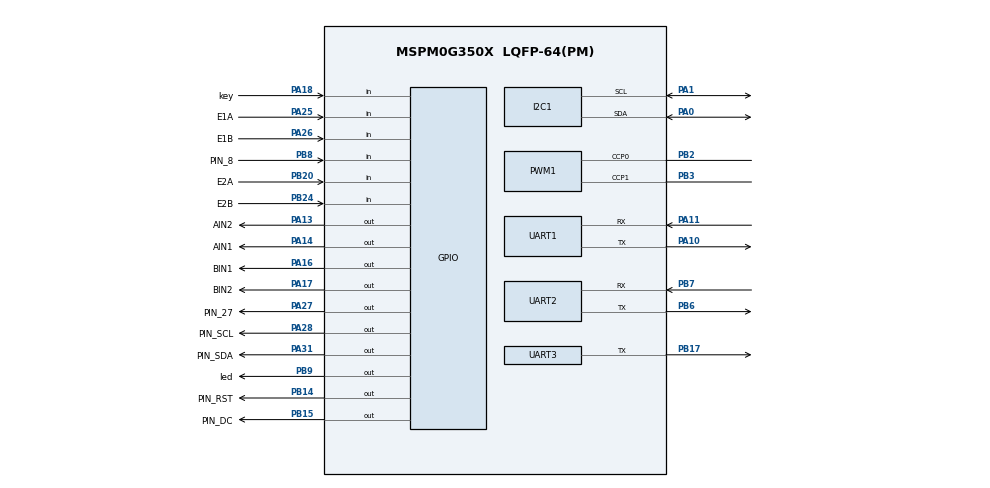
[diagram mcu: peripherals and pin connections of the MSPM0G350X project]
/**
 * @cliArgs --device "MSPM0G350X" --package "LQFP-64(PM)" --part "Default" --product "mspm0_sdk@2.01.00.03"
 * @versions {"tool":"1.20.0+3587"}
 */

/**
 * Import the modules used in this configuration.
 */
const Board   = scripting.addModule("/ti/driverlib/Board");
const GPIO    = scripting.addModule("/ti/driverlib/GPIO", {}, false);
const GPIO1   = GPIO.addInstance();
const GPIO2   = GPIO.addInstance();
const GPIO3   = GPIO.addInstance();
const GPIO4   = GPIO.addInstance();
const GPIO5   = GPIO.addInstance();
const GPIO6   = GPIO.addInstance();
const GPIO7   = GPIO.addInstance();
const GPIO8   = GPIO.addInstance();
const GPIO9   = GPIO.addInstance();
const GPIO10  = GPIO.addInstance();
const GPIO11  = GPIO.addInstance();
const GPIO12  = GPIO.addInstance();
const GPIO13  = GPIO.addInstance();
const GPIO14  = GPIO.addInstance();
const GPIO15  = GPIO.addInstance();
const GPIO16  = GPIO.addInstance();
const I2C     = scripting.addModule("/ti/driverlib/I2C", {}, false);
const I2C1    = I2C.addInstance();
const PWM     = scripting.addModule("/ti/driverlib/PWM", {}, false);
const PWM1    = PWM.addInstance();
const SYSCTL  = scripting.addModule("/ti/driverlib/SYSCTL");
const SYSTICK = scripting.addModule("/ti/driverlib/SYSTICK");
const TIMER   = scripting.addModule("/ti/driverlib/TIMER", {}, false);
const TIMER1  = TIMER.addInstance();
const UART    = scripting.addModule("/ti/driverlib/UART", {}, false);
const UART1   = UART.addInstance();
const UART2   = UART.addInstance();
const UART3   = UART.addInstance();

/**
 * Write custom configuration values to the imported modules.
 */
const divider7       = system.clockTree["PLL_PDIV"];
divider7.divideValue = 2;

const divider9       = system.clockTree["UDIV"];
divider9.divideValue = 2;

const gate7  = system.clockTree["MFCLKGATE"];
gate7.enable = true;

const gate8  = system.clockTree["MFPCLKGATE"];
gate8.enable = true;

const multiplier2         = system.clockTree["PLL_QDIV"];
multiplier2.multiplyValue = 5;

const mux2       = system.clockTree["CANCLKMUX"];
mux2.inputSelect = "CANCLKMUX_PLLCLK1_OUT";

const mux8       = system.clockTree["HSCLKMUX"];
mux8.inputSelect = "HSCLKMUX_SYSPLL2X";

Board.debugOn = false;

GPIO1.$name                               = "ENCODERA";
GPIO1.associatedPins.create(2);
GPIO1.associatedPins[0].$name             = "E1A";
GPIO1.associatedPins[0].direction         = "INPUT";
GPIO1.associatedPins[0].interruptEn       = true;
GPIO1.associatedPins[0].interruptPriority = "0";
GPIO1.associatedPins[0].polarity          = "RISE";
GPIO1.associatedPins[0].pin.$assign       = "PA25";
GPIO1.associatedPins[1].$name             = "E1B";
GPIO1.associatedPins[1].direction         = "INPUT";
GPIO1.associatedPins[1].interruptEn       = true;
GPIO1.associatedPins[1].interruptPriority = "0";
GPIO1.associatedPins[1].polarity          = "RISE";
GPIO1.associatedPins[1].pin.$assign       = "PA26";

GPIO2.$name                               = "ENCODERB";
GPIO2.associatedPins.create(2);
GPIO2.associatedPins[0].direction         = "INPUT";
GPIO2.associatedPins[0].$name             = "E2A";
GPIO2.associatedPins[0].interruptEn       = true;
GPIO2.associatedPins[0].interruptPriority = "0";
GPIO2.associatedPins[0].polarity          = "RISE";
GPIO2.associatedPins[0].pin.$assign       = "PB20";
GPIO2.associatedPins[1].$name             = "E2B";
GPIO2.associatedPins[1].direction         = "INPUT";
GPIO2.associatedPins[1].interruptEn       = true;
GPIO2.associatedPins[1].interruptPriority = "0";
GPIO2.associatedPins[1].polarity          = "RISE";
GPIO2.associatedPins[1].pin.$assign       = "PB24";

GPIO3.$name                         = "AIN";
GPIO3.port                          = "PORTA";
GPIO3.associatedPins.create(2);
GPIO3.associatedPins[0].$name       = "AIN1";
GPIO3.associatedPins[0].pin.$assign = "PA14";
GPIO3.associatedPins[1].$name       = "AIN2";
GPIO3.associatedPins[1].pin.$assign = "PA13";

GPIO4.$name                         = "BIN";
GPIO4.port                          = "PORTA";
GPIO4.associatedPins.create(2);
GPIO4.associatedPins[0].$name       = "BIN1";
GPIO4.associatedPins[0].pin.$assign = "PA16";
GPIO4.associatedPins[1].$name       = "BIN2";
GPIO4.associatedPins[1].pin.$assign = "PA17";

GPIO5.$name                         = "LED";
GPIO5.associatedPins[0].$name       = "led";
GPIO5.associatedPins[0].pin.$assign = "PB9";

GPIO6.$name                              = "KEY";
GPIO6.associatedPins[0].$name            = "key";
GPIO6.associatedPins[0].direction        = "INPUT";
GPIO6.associatedPins[0].internalResistor = "PULL_DOWN";
GPIO6.associatedPins[0].pin.$assign      = "PA18";

GPIO7.$name                         = "OLED_RST";
GPIO7.associatedPins[0].$name       = "PIN_RST";
GPIO7.associatedPins[0].pin.$assign = "PB14";

GPIO8.$name                         = "OLED_DC";
GPIO8.associatedPins[0].$name       = "PIN_DC";
GPIO8.associatedPins[0].pin.$assign = "PB15";

GPIO9.$name                         = "OLED_SCL";
GPIO9.associatedPins[0].$name       = "PIN_SCL";
GPIO9.associatedPins[0].pin.$assign = "PA28";

GPIO10.$name                         = "OLED_SDA";
GPIO10.associatedPins[0].$name       = "PIN_SDA";
GPIO10.associatedPins[0].pin.$assign = "PA31";

GPIO11.port                          = "PORTA";
GPIO11.$name                         = "IR_AD0";
GPIO11.associatedPins[0].$name       = "PIN_9";
GPIO11.associatedPins[0].assignedPin = "9";

GPIO12.port                          = "PORTA";
GPIO12.$name                         = "IR_AD1";
GPIO12.associatedPins[0].$name       = "PIN_27";
GPIO12.associatedPins[0].assignedPin = "27";
GPIO12.associatedPins[0].pin.$assign = "PA27";

GPIO13.port                          = "PORTA";
GPIO13.$name                         = "IR_AD2";
GPIO13.associatedPins[0].assignedPin = "24";
GPIO13.associatedPins[0].$name       = "PIN_24";

GPIO14.$name                         = "IR_OUT";
GPIO14.port                          = "PORTA";
GPIO14.associatedPins[0].direction   = "INPUT";
GPIO14.associatedPins[0].$name       = "PIN_12";
GPIO14.associatedPins[0].assignedPin = "12";

GPIO16.$name                         = "KEY2";
GPIO16.associatedPins[0].$name       = "PIN_8";
GPIO16.associatedPins[0].direction   = "INPUT";
GPIO16.associatedPins[0].internalResistor = "PULL_DOWN";
GPIO16.associatedPins[0].pin.$assign = "PB8";

I2C1.$name                           = "I2C_0";
I2C1.basicEnableController           = true;
I2C1.basicControllerStandardBusSpeed = "Fast";
I2C1.peripheral.$assign              = "I2C0";
I2C1.peripheral.sdaPin.$assign       = "PA0";
I2C1.peripheral.sclPin.$assign       = "PA1";
I2C1.sdaPinConfig.$name              = "ti_driverlib_gpio_GPIOPinGeneric8";
I2C1.sclPinConfig.$name              = "ti_driverlib_gpio_GPIOPinGeneric9";

PWM1.$name                      = "PWM_0";
PWM1.timerStartTimer            = true;
PWM1.pwmMode                    = "EDGE_ALIGN_UP";
PWM1.timerCount                 = 8000;
PWM1.peripheral.$assign         = "TIMA1";
PWM1.peripheral.ccp0Pin.$assign = "PB2";
PWM1.peripheral.ccp1Pin.$assign = "PB3";
PWM1.PWM_CHANNEL_0.$name        = "ti_driverlib_pwm_PWMTimerCC0";
PWM1.PWM_CHANNEL_1.$name        = "ti_driverlib_pwm_PWMTimerCC1";
PWM1.ccp0PinConfig.$name        = "ti_driverlib_gpio_GPIOPinGeneric4";
PWM1.ccp1PinConfig.$name        = "ti_driverlib_gpio_GPIOPinGeneric5";

SYSCTL.forceDefaultClkConfig = true;
SYSCTL.clockTreeEn           = true;

SYSTICK.periodEnable  = true;
SYSTICK.systickEnable = true;
SYSTICK.period        = 16777216;

TIMER1.$name              = "TIMER_0";
TIMER1.timerClkPrescale   = 32;
TIMER1.timerMode          = "PERIODIC";
TIMER1.timerPeriod        = "10 ms";
TIMER1.timerStartTimer    = true;
TIMER1.interrupts         = ["ZERO"];
TIMER1.peripheral.$assign = "TIMG0";

UART1.$name                    = "UART_0";
UART1.targetBaudRate           = 115200;
UART1.enableFIFO               = true;
UART1.rxFifoThreshold          = "DL_UART_RX_FIFO_LEVEL_ONE_ENTRY";
UART1.enableDMARX              = false;
UART1.enableDMATX              = false;
UART1.peripheral.$assign       = "UART0";
UART1.peripheral.rxPin.$assign = "PA11";
UART1.peripheral.txPin.$assign = "PA10";
UART1.txPinConfig.$name        = "ti_driverlib_gpio_GPIOPinGeneric0";
UART1.rxPinConfig.$name        = "ti_driverlib_gpio_GPIOPinGeneric1";

UART2.$name                    = "UART_1";
UART2.targetBaudRate           = 115200;
UART2.enableFIFO               = true;
UART2.rxFifoThreshold          = "DL_UART_RX_FIFO_LEVEL_ONE_ENTRY";
UART2.enabledInterrupts        = ["RX"];
UART2.peripheral.rxPin.$assign = "PB7";
UART2.peripheral.txPin.$assign = "PB6";
UART2.txPinConfig.$name        = "ti_driverlib_gpio_GPIOPinGeneric6";
UART2.rxPinConfig.$name        = "ti_driverlib_gpio_GPIOPinGeneric7";

UART3.$name                    = "UART_2";
UART3.targetBaudRate           = 115200;
UART3.peripheral.txPin.$assign = "PB17";
UART3.txPinConfig.$name        = "ti_driverlib_gpio_GPIOPinGeneric2";
UART3.rxPinConfig.$name        = "ti_driverlib_gpio_GPIOPinGeneric3";

/**
 * Pinmux solution for unlocked pins/peripherals. This ensures that minor changes to the automatic solver in a future
 * version of the tool will not impact the pinmux you originally saw.  These lines can be completely deleted in order to
 * re-solve from scratch.
 */
Board.peripheral.$suggestSolution             = "DEBUGSS";
GPIO11.associatedPins[0].pin.$suggestSolution = "PA9";
GPIO13.associatedPins[0].pin.$suggestSolution = "PA24";
GPIO14.associatedPins[0].pin.$suggestSolution = "PA12";
GPIO15.associatedPins[0].pin.$suggestSolution = "PA22";
UART2.peripheral.$suggestSolution             = "UART1";
UART3.peripheral.$suggestSolution             = "UART2";
UART3.peripheral.rxPin.$suggestSolution       = "PB16";
